# pwrseq_me13 register map
Registers are access not given, no defined reset value unless marked. A register's access mark holds for its fields unless they carry their own. Offsets are from the block's base; lines under a group give offsets from that group; [hi:lo] are bit positions; {n}, {i} and the like mark numbered series; 'fields as' and 'values as' point back to an identical list; <NAME> marks a mode.

## Memory map
0x40006800 PWRSEQ size 0x400 — Power Sequencer / Low Power Control Register.

## PWRSEQ — Power Sequencer / Low Power Control Register.
Base 0x40006800
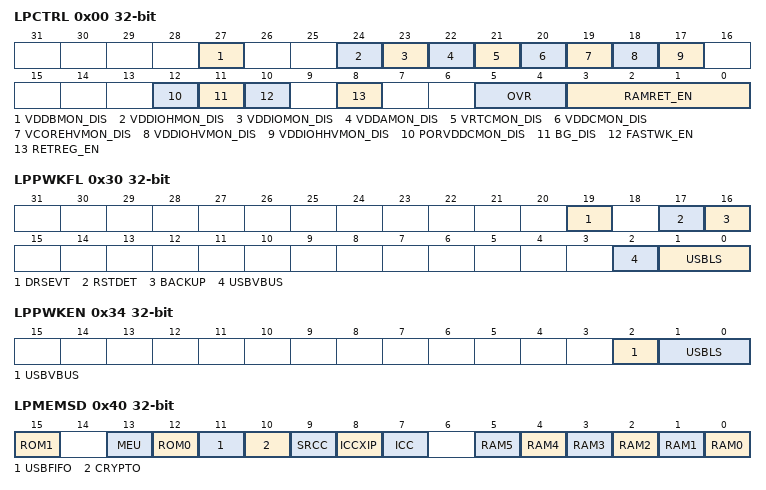
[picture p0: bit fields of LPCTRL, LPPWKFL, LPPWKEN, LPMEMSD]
0x00 LPCTRL — Low Power Control Register.
  [27] VDDBMON_DIS — VDDB Monitor Disable. This bit controls the Power-On Reset monitor on VDDB supply in all operating mods.
    0=dis (Disabled.); 1=en (Enabled.)
  [24] VDDIOHMON_DIS — VDDIOH Monitor Disable. This bit controls the power monitor of the Analog Supply in all operating modes.
    0=en (Enable if Bandgap is ON (default)); 1=dis (Disabled.)
  [23] VDDIOMON_DIS — VDDIO Monitor Disable. This bit controls the power monitor of the Analog Supply in all operating modes.
    0=en (Enable if Bandgap is ON (default)); 1=dis (Disabled.)
  [22] VDDAMON_DIS — VDDA Monitor Disable. This bit controls the power monitor of the Analog Supply in all operating modes.
    0=en (Enable if Bandgap is ON (default)); 1=dis (Disabled.)
  [21] VRTCMON_DIS — VRTC Monitor Disable. This bit controls the power monitor on the Always-On Supply in all operating modes.
    0=en (Enable if Bandgap is ON (default)); 1=dis (Disabled.)
  [20] VDDCMON_DIS — VDDC (Vcore) Monitor Disable. This bit controls the power monitor on the VCore supply in all operating modes.
    0=en (Enable if Bandgap is ON (default)); 1=dis (Disabled.)
  [19] VCOREHVMON_DIS — VCORE High Voltage Monitor Disable. This bit controls the power monitor on VCORE supply in all operating modes.
  [18] VDDIOHVMON_DIS — VDDIO High Voltage Monitor Disable. This bit controls the power monitor on VDDIO supply in all operating modes.
  [17] VDDIOHHVMON_DIS — VDDIOH High Voltage Monitor Disable. This bit controls the power monitor on VDDIOH supply in all operating modes.
  [12] PORVDDCMON_DIS — VDDC (VCore) Power-On Reset Monitor Disable. This bit controls the Power-On Reset monitor on VDDC supply in DeepSleep and BACKUP mode.
  [11] BG_DIS — Bandgap OFF. This controls the System Bandgap in DeepSleep mode.
    0=on (Bandgap is always ON.); 1=off (Bandgap is OFF in DeepSleep mode (default).)
  [10] FASTWK_EN — Fast Wake-Up Mode. This bit enables fast wake-up from DeepSleep mode. (5uS typical).
    0=dis (Disabled.); 1=en (Enabled.)
  [8] RETREG_EN — Retention Regulator Enable. This bit controls the retention regulator in BACKUP mode.
    0=dis (Disabled.); 1=en (Enabled.)
  [5:4] OVR — Operating Voltage Range
    2=1_1V
  [3:0] RAMRET_EN — System RAM retention in BACKUP mode. These two bits are used in conjuction with RREGEN bit.
{0x4+8i} LPWKFL{i} (i=0..3) — Low Power I/O Wakeup Status Register {i}. This register indicates the low power wakeup status for GPIO{i}.
  [30:0] ALL — Wakeup Flags.
{0x8+8i} LPWKEN{i} (i=0..3) — Low Power I/O Wakeup Enable Register {i}. This register enables low power wakeup functionality for GPIO{i}.
  [30:0] ALL — Enable wakeup. These bits allow wakeup from the corresponding GPIO pin (s) on transition (s) from low to high or high to low when PM.GPIOWKEN is set. Wakeup status is indicated in PPWKST register.
0x30 LPPWKFL — Low Power Peripheral Wakeup Status Register.
  [19] DRSEVT — DRS Event Wakeup Flag.
  [17] RSTDET — Reset Detect Wakeup Flag (write one to clear). This bit will be set when the external reset causes wakeup
  [16] BACKUP — Battery Back Wakeup Flag (write one to clear). This bit will be set when exiting Battery Backup Mode.
  [2] USBVBUS — USB VBUS Detect Wakeup Flag (write one to clear). This bit will be set when the USB power supply is powered on or powered off.
  [1:0] USBLS — USB UTMI Linestate Detect Wakeup Flag (write one to clear). One or both of these bits will be set when the USB bus activity causes the linestate to change and the device to wake while USB wakeup is enabled using PMLUSBWKEN.
0x34 LPPWKEN — Low Power Peripheral Wakeup Enable Register.
  [2] USBVBUS — USB VBUS Detect Wakeup Enable. This bit allows wakeup from the USB power supply on or off status.
  [1:0] USBLS — USB UTMI Linestate Detect Wakeup Enable. These bits allow wakeup from the corresponding USB linestate signal (s) on transition (s) from low to high or high to low when PM.USBWKEN is set.
0x40 LPMEMSD — Low Power Memory Shutdown Control.
  [all] fields
    0=Normal Operating Mode; 1=Shutdown Mode
  [15] ROM1 — ROM1 Shut Down.
  [13] MEU — MEU MEM Shut Down.
  [12] ROM0 — ROM0 Shut Down. (CPU0 ROM)
  [11] USBFIFO — USB FIFO Shut Down.
  [10] CRYPTO — Crypto Memory (MAA) Shut Down.
  [9] SRCC — System Cache RAM Shut Down.
  [8] ICCXIP — XiP Instruction Cache RAM Shut Down.
  [7] ICC — Instruction Cache RAM Shut Down.
  [n] RAM{n} (n=0..5) — System RAM block {n} Shut Down.
0x44 LPVDDPD — Low Power VDD Domain Power Down Control.
0x48 GP0 — General Purpose Register 0
0x4C GP1 — General Purpose Register 1
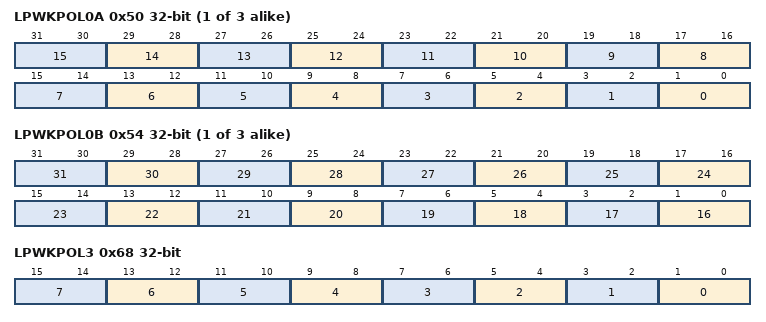
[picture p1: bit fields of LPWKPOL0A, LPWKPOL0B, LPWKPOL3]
{0x50+8i} LPWKPOL{i}A (i=0..2) — Low Power Wakeup Polarity Select for GPIO{i}.
  [all] fields
    0=BOTH_EDGES; 1=RISING (Rising Edge.); 2=FALLING (Falling Edge.)
  [2n+1:2n] {n} (n=0..15) — Polarity Select for Wakeup Events for Pin {n}.
{0x54+8i} LPWKPOL{i}B (i=0..2) — Low Power Wakeup Polarity Select for GPIO{i}.
  [all] fields
    values as the fields of LPWKPOL0A
  [2n-31:2n-32] {n} (n=16..31) — Polarity Select for Wakeup Events for Pin {n}.
0x68 LPWKPOL3 — Low Power Wakeup Polarity Select for GPIO3.
  [all] fields
    values as the fields of LPWKPOL0A
  [2n+1:2n] {n} (n=0..7) — Polarity Select for Wakeup Events for Pin {n}.
